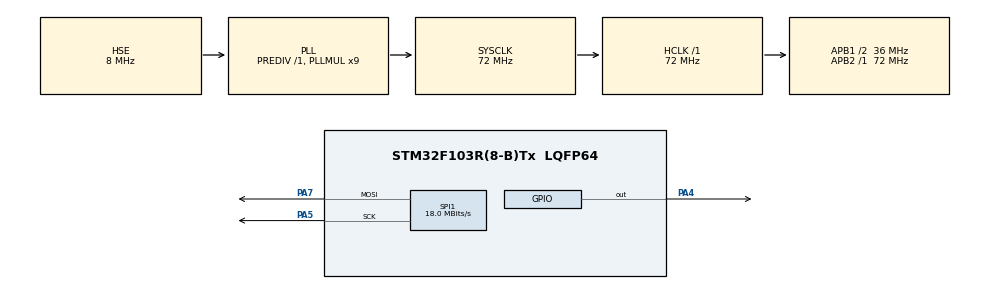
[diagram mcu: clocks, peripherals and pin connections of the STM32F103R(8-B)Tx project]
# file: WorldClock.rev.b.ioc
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Dma.Request0=SPI1_TX
Dma.SPI1_TX.0.Direction=DMA_MEMORY_TO_PERIPH
Dma.SPI1_TX.0.Instance=DMA1_Channel3
Dma.SPI1_TX.0.MemDataAlignment=DMA_MDATAALIGN_BYTE
Dma.SPI1_TX.0.MemInc=DMA_MINC_ENABLE
Dma.SPI1_TX.0.Mode=DMA_NORMAL
Dma.SPI1_TX.0.PeriphDataAlignment=DMA_PDATAALIGN_BYTE
Dma.SPI1_TX.0.PeriphInc=DMA_PINC_DISABLE
Dma.SPI1_TX.0.Priority=DMA_PRIORITY_LOW
FREERTOS.Tasks01=vLED,0,128,vLEDTask,Default
Mcu.Family=STM32F1
Mcu.Name=STM32F103R(8-B)Tx
Mcu.Package=LQFP64
NVIC.DMA1_Channel3_IRQn=true\:5\:0\:false
NVIC.PriorityGroup=NVIC_PRIORITYGROUP_4
NVIC.TIM3_IRQn=true\:5\:0\:false
PA4.Signal=GPIO_Output
PA5.Mode=TX_Only_Simplex_Unidirect_Master
PA5.Signal=SPI1_SCK
PA7.Mode=TX_Only_Simplex_Unidirect_Master
PA7.Signal=SPI1_MOSI
PD0-OSC_IN.Mode=HSE-External-Clock-Source
PD0-OSC_IN.Signal=RCC_OSC_IN
PD1-OSC_OUT.Mode=HSE-External-Clock-Source
PD1-OSC_OUT.Signal=RCC_OSC_OUT
ProjectManager.HeapSize=0x400
ProjectManager.StackSize=0x200
ProjectManager.TargetToolchain=MDK-ARM V5
RCC.AHBFreq_Value=72000000
RCC.APB1CLKDivider=RCC_HCLK_DIV2
RCC.APB1Freq_Value=36000000
RCC.APB1TimFreq_Value=72000000
RCC.APB2Freq_Value=72000000
RCC.APB2TimFreq_Value=72000000
RCC.HCLKFreq_Value=72000000
RCC.HSIState=RCC_HSI_ON
RCC.PLLMUL=RCC_PLL_MUL9
RCC.PLLSourceVirtual=RCC_PLLSOURCE_HSE
RCC.SYSCLKFreq_VALUE=72000000
RCC.SYSCLKSource=RCC_SYSCLKSOURCE_PLLCLK
RCC.USBFreq_Value=72000000
SPI1.BaudRatePrescaler=SPI_BAUDRATEPRESCALER_4
SPI1.CLKPhase=SPI_PHASE_2EDGE
SPI1.CLKPolarity=SPI_POLARITY_HIGH
SPI1.CalculateBaudRate=18.0 MBits/s
SPI1.Mode=SPI_MODE_MASTER
TIM3.Period=71
TIM3.Prescaler=15
VP_FREERTOS_VS_ENABLE.Mode=Enabled
VP_TIM3_VS_ClockSourceINT.Mode=Internal
board=WorldClock.rev.b

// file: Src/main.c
/**
  ******************************************************************************
  * File Name          : main.c
  * Description        : Main program body
  ******************************************************************************
  *
  * COPYRIGHT(c) 2016 STMicroelectronics
  *
  * Redistribution and use in source and binary forms, with or without modification,
  * are permitted provided that the following conditions are met:
  *   1. Redistributions of source code must retain the above copyright notice,
  *      this list of conditions and the following disclaimer.
  *   2. Redistributions in binary form must reproduce the above copyright notice,
  *      this list of conditions and the following disclaimer in the documentation
  *      and/or other materials provided with the distribution.
  *   3. Neither the name of STMicroelectronics nor the names of its contributors
  *      may be used to endorse or promote products derived from this software
  *      without specific prior written permission.
  *
  * THIS SOFTWARE IS PROVIDED BY THE COPYRIGHT HOLDERS AND CONTRIBUTORS "AS IS"
  * AND ANY EXPRESS OR IMPLIED WARRANTIES, INCLUDING, BUT NOT LIMITED TO, THE
  * IMPLIED WARRANTIES OF MERCHANTABILITY AND FITNESS FOR A PARTICULAR PURPOSE ARE
  * DISCLAIMED. IN NO EVENT SHALL THE COPYRIGHT HOLDER OR CONTRIBUTORS BE LIABLE
  * FOR ANY DIRECT, INDIRECT, INCIDENTAL, SPECIAL, EXEMPLARY, OR CONSEQUENTIAL
  * DAMAGES (INCLUDING, BUT NOT LIMITED TO, PROCUREMENT OF SUBSTITUTE GOODS OR
  * SERVICES; LOSS OF USE, DATA, OR PROFITS; OR BUSINESS INTERRUPTION) HOWEVER
  * CAUSED AND ON ANY THEORY OF LIABILITY, WHETHER IN CONTRACT, STRICT LIABILITY,
  * OR TORT (INCLUDING NEGLIGENCE OR OTHERWISE) ARISING IN ANY WAY OUT OF THE USE
  * OF THIS SOFTWARE, EVEN IF ADVISED OF THE POSSIBILITY OF SUCH DAMAGE.
  *
  ******************************************************************************
  */
#include "stm32f1xx_hal.h"
#include "cmsis_os.h"

SPI_HandleTypeDef hspi1;
DMA_HandleTypeDef hdma_spi1_tx;

TIM_HandleTypeDef htim3;

osThreadId vLEDHandle;

/* USER CODE BEGIN PV */
/* Private variables ---------------------------------------------------------*/

#define disfps		16
#define disbufNum	4

uint8_t	disBuf[disbufNum][12][7];
uint8_t disIMG[12][12];
const uint16_t disMap[12] = { 0x0010, 0x0008, 0x0004, 0x0002, 0x0020, 0x8000, 0x4000, 0x2000, 0x1000, 0x0800, 0x0400, 0x0200 };
/* USER CODE END PV */

void SystemClock_Config(void);
static void MX_GPIO_Init(void);
static void MX_DMA_Init(void);
static void MX_SPI1_Init(void);
static void MX_TIM3_Init(void);
void vLEDTask(void const * argument);

/* USER CODE BEGIN PFP */
/* Private function prototypes -----------------------------------------------*/

/* USER CODE END PFP */

/* USER CODE BEGIN 0 */
void HAL_SPI_TxCpltCallback(SPI_HandleTypeDef *hspi)
{
	HAL_GPIO_WritePin(GPIOA,GPIO_PIN_4,GPIO_PIN_SET);
	HAL_GPIO_WritePin(GPIOA,GPIO_PIN_4,GPIO_PIN_RESET);
}

void HAL_TIM_PeriodElapsedCallback(TIM_HandleTypeDef *htim)
{
	static uint16_t listNum = 0;
	listNum += 7;
	if (listNum >= (disbufNum * 12 * 7))
		listNum = 0;
	HAL_SPI_Transmit_DMA(&hspi1,(uint8_t *)disBuf+listNum,7);
}

void SetPiont(void)
{
	uint8_t listNum;
	uint8_t fpsNum;
	uint64_t tmp;
	uint8_t rgb;
	uint8_t i;

	for (fpsNum = 0; fpsNum < disbufNum;fpsNum++)
		for (listNum = 0; listNum < 12; listNum++)
		{
			tmp = 0;

			for(i=0;i<12;i++)
			{
				rgb = disIMG[11-i][listNum];

				tmp <<= 3;
				if(((rgb>>6) & 0x03) > fpsNum)		//red
					tmp |= 0x02;
				if(((rgb>>4) & 0x03) > fpsNum)		//green
				{
					if (listNum & 0x01)
						tmp |= 0x01;
					else
						tmp |= 0x04;
				}
				if(((rgb>>2) & 0x03) > fpsNum)		//blue
				{
					if (listNum & 0x01)
						tmp |= 0x04;
					else
						tmp |= 0x01;
				}
			}

			disBuf[fpsNum][listNum][0] = disMap[listNum] >> 8;
			disBuf[fpsNum][listNum][1] = disMap[listNum] & 0xff;
			disBuf[fpsNum][listNum][2] = (tmp>>32)&0xff;
			disBuf[fpsNum][listNum][3] = (tmp>>24)&0xff;
			disBuf[fpsNum][listNum][4] = (tmp>>16)&0xff;
			disBuf[fpsNum][listNum][5] = (tmp>>8 )&0xff;
			disBuf[fpsNum][listNum][6] = (tmp>>0 )&0xff;
		}
}

void TheMatrix(void)
{
	uint16_t i,k,tmp;
	static uint16_t m[12] = {3354, 2578, 4056, 3156, 1570, 3234, 2834, 5080, 3970, 1678, 3345, 2127};
	static uint16_t n[12] = {21, 18, 14, 19, 14, 17, 12, 16, 18, 21, 16, 23};
	static uint16_t o[12] = {0};
	for(i=0;i<12;i++)
	{
		o[i]+=m[i];

		for(k=0;k<12;k++)
		{
			tmp = o[i]*n[i]/65536.0;
			//tmp = 2;
			if(k == tmp)
				disIMG[k][i] = 0x30;
			else if((k == (tmp-1))||(k == (tmp+n[i]-1)))
				disIMG[k][i] = 0x20;
			else if((k == (tmp-2))||(k == (tmp+n[i]-2)))
				disIMG[k][i] = 0x20;
			else if((k == (tmp-3))||(k == (tmp+n[i]-3)))
				disIMG[k][i] = 0x10;
			else if((k == (tmp-4))||(k == (tmp+n[i]-4)))
				disIMG[k][i] = 0x10;
			else if((k == (tmp-5))||(k == (tmp+n[i]-5)))
				disIMG[k][i] = 0x10;
			else
				disIMG[k][i] = 0x00;

			if((k<3)&(disIMG[k][i]==0x20))
				disIMG[k][i] = 0x30;
		}
	}
	SetPiont();
	osDelay(75);
}
/* USER CODE END 0 */

int main(void)
{

  /* MCU Configuration----------------------------------------------------------*/

  /* Reset of all peripherals, Initializes the Flash interface and the Systick. */
  HAL_Init();

  /* Configure the system clock */
  SystemClock_Config();

  /* Initialize all configured peripherals */
  MX_GPIO_Init();
  MX_DMA_Init();
  MX_SPI1_Init();
  MX_TIM3_Init();

  /* Create the thread(s) */
  /* definition and creation of vLED */
  osThreadDef(vLED, vLEDTask, osPriorityNormal, 0, 128);
  vLEDHandle = osThreadCreate(osThread(vLED), NULL);

  /* Start scheduler */
  osKernelStart();

  /* We should never get here as control is now taken by the scheduler */

  /* Infinite loop */
  while (1)
  {

  }

}

/** System Clock Configuration
*/
void SystemClock_Config(void)
{

  RCC_OscInitTypeDef RCC_OscInitStruct;
  RCC_ClkInitTypeDef RCC_ClkInitStruct;

  RCC_OscInitStruct.OscillatorType = RCC_OSCILLATORTYPE_HSE;
  RCC_OscInitStruct.HSEState = RCC_HSE_BYPASS;
  RCC_OscInitStruct.HSEPredivValue = RCC_HSE_PREDIV_DIV1;
  RCC_OscInitStruct.PLL.PLLState = RCC_PLL_ON;
  RCC_OscInitStruct.PLL.PLLSource = RCC_PLLSOURCE_HSE;
  RCC_OscInitStruct.PLL.PLLMUL = RCC_PLL_MUL9;
  HAL_RCC_OscConfig(&RCC_OscInitStruct);

  RCC_ClkInitStruct.ClockType = RCC_CLOCKTYPE_HCLK|RCC_CLOCKTYPE_SYSCLK
                              |RCC_CLOCKTYPE_PCLK1|RCC_CLOCKTYPE_PCLK2;
  RCC_ClkInitStruct.SYSCLKSource = RCC_SYSCLKSOURCE_PLLCLK;
  RCC_ClkInitStruct.AHBCLKDivider = RCC_SYSCLK_DIV1;
  RCC_ClkInitStruct.APB1CLKDivider = RCC_HCLK_DIV2;
  RCC_ClkInitStruct.APB2CLKDivider = RCC_HCLK_DIV1;
  HAL_RCC_ClockConfig(&RCC_ClkInitStruct, FLASH_LATENCY_2);

  HAL_SYSTICK_Config(HAL_RCC_GetHCLKFreq()/1000);

  HAL_SYSTICK_CLKSourceConfig(SYSTICK_CLKSOURCE_HCLK);

  /* SysTick_IRQn interrupt configuration */
  HAL_NVIC_SetPriority(SysTick_IRQn, 15, 0);
}

/* SPI1 init function */
void MX_SPI1_Init(void)
{

  hspi1.Instance = SPI1;
  hspi1.Init.Mode = SPI_MODE_MASTER;
  hspi1.Init.Direction = SPI_DIRECTION_2LINES;
  hspi1.Init.DataSize = SPI_DATASIZE_8BIT;
  hspi1.Init.CLKPolarity = SPI_POLARITY_HIGH;
  hspi1.Init.CLKPhase = SPI_PHASE_2EDGE;
  hspi1.Init.NSS = SPI_NSS_SOFT;
  hspi1.Init.BaudRatePrescaler = SPI_BAUDRATEPRESCALER_4;
  hspi1.Init.FirstBit = SPI_FIRSTBIT_MSB;
  hspi1.Init.TIMode = SPI_TIMODE_DISABLED;
  hspi1.Init.CRCCalculation = SPI_CRCCALCULATION_DISABLED;
  hspi1.Init.CRCPolynomial = 10;
  HAL_SPI_Init(&hspi1);

}

/* TIM3 init function */
void MX_TIM3_Init(void)
{

  TIM_ClockConfigTypeDef sClockSourceConfig;
  TIM_MasterConfigTypeDef sMasterConfig;

  htim3.Instance = TIM3;
  htim3.Init.Prescaler = 15;
  htim3.Init.CounterMode = TIM_COUNTERMODE_UP;
  htim3.Init.Period = 71;
  htim3.Init.ClockDivision = TIM_CLOCKDIVISION_DIV1;
  HAL_TIM_Base_Init(&htim3);

  sClockSourceConfig.ClockSource = TIM_CLOCKSOURCE_INTERNAL;
  HAL_TIM_ConfigClockSource(&htim3, &sClockSourceConfig);

  sMasterConfig.MasterOutputTrigger = TIM_TRGO_RESET;
  sMasterConfig.MasterSlaveMode = TIM_MASTERSLAVEMODE_DISABLE;
  HAL_TIMEx_MasterConfigSynchronization(&htim3, &sMasterConfig);

}

void MX_DMA_Init(void)
{
  /* DMA controller clock enable */
  __HAL_RCC_DMA1_CLK_ENABLE();

  /* DMA interrupt init */
  HAL_NVIC_SetPriority(DMA1_Channel3_IRQn, 5, 0);
  HAL_NVIC_EnableIRQ(DMA1_Channel3_IRQn);

}

/** Configure pins as
        * Analog
        * Input
        * Output
        * EVENT_OUT
        * EXTI
*/
void MX_GPIO_Init(void)
{

  GPIO_InitTypeDef GPIO_InitStruct;

  /* GPIO Ports Clock Enable */
  __GPIOD_CLK_ENABLE();
  __GPIOA_CLK_ENABLE();

  /*Configure GPIO pin Output Level */
  HAL_GPIO_WritePin(GPIOA, GPIO_PIN_4, GPIO_PIN_RESET);

  /*Configure GPIO pin : PA4 */
  GPIO_InitStruct.Pin = GPIO_PIN_4;
  GPIO_InitStruct.Mode = GPIO_MODE_OUTPUT_PP;
  GPIO_InitStruct.Speed = GPIO_SPEED_LOW;
  HAL_GPIO_Init(GPIOA, &GPIO_InitStruct);

}

/* vLEDTask function */
void vLEDTask(void const * argument)
{

  /* USER CODE BEGIN 5 */
	HAL_TIM_Base_Start_IT(&htim3);
  /* Infinite loop */
  for(;;)
  {
		TheMatrix();
  }
  /* USER CODE END 5 */
}

/************************ (C) COPYRIGHT STMicroelectronics *****END OF FILE****/
